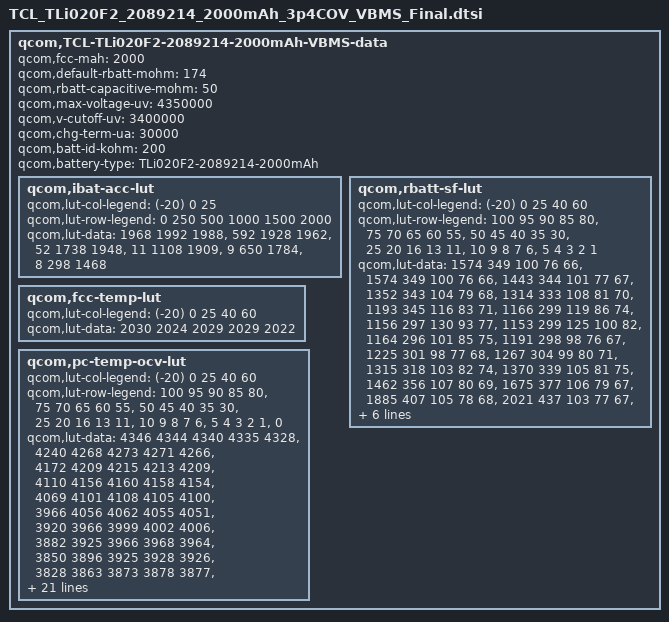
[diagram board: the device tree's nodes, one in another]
 qcom,TCL-TLi020F2-2089214-2000mAh-VBMS-data {
	qcom,fcc-mah = <2000>;
	qcom,default-rbatt-mohm = <174>;
	qcom,rbatt-capacitive-mohm = <50>;
	qcom,max-voltage-uv = <4350000>;
	qcom,v-cutoff-uv = <3400000>;
	qcom,chg-term-ua = <30000>;
	qcom,batt-id-kohm = <200>;
	qcom,battery-type = "TLi020F2-2089214-2000mAh";

	qcom,ibat-acc-lut {
		qcom,lut-col-legend = <(-20) 0 25>;
		qcom,lut-row-legend = <0 250 500 1000 1500 2000>;
		qcom,lut-data = <1968 1992 1988>,
				<592 1928 1962>,
				<52 1738 1948>,
				<11 1108 1909>,
				<9 650 1784>,
				<8 298 1468>;
	};

	qcom,rbatt-sf-lut {
		qcom,lut-col-legend = <(-20) 0 25 40 60>;
		qcom,lut-row-legend = <100 95 90 85 80>,
				<75 70 65 60 55>,
				<50 45 40 35 30>,
				<25 20 16 13 11>,
				<10 9 8 7 6>,
				<5 4 3 2 1>;
		qcom,lut-data = <1574 349 100 76 66>,
				<1574 349 100 76 66>,
				<1443 344 101 77 67>,
				<1352 343 104 79 68>,
				<1314 333 108 81 70>,
				<1193 345 116 83 71>,
				<1166 299 119 86 74>,
				<1156 297 130 93 77>,
				<1153 299 125 100 82>,
				<1164 296 101 85 75>,
				<1191 298 98 76 67>,
				<1225 301 98 77 68>,
				<1267 304 99 80 71>,
				<1315 318 103 82 74>,
				<1370 339 105 81 75>,
				<1462 356 107 80 69>,
				<1675 377 106 79 67>,
				<1885 407 105 78 68>,
				<2021 437 103 77 67>,
				<1834 430 103 78 68>,
				<1977 443 105 79 70>,
				<2151 459 109 82 71>,
				<2349 478 113 84 74>,
				<2593 497 118 87 76>,
				<2906 517 123 89 78>,
				<3354 537 122 86 71>,
				<4026 560 121 85 73>,
				<5346 602 129 92 78>,
				<10692 668 156 113 98>,
				<21384 1336 313 226 124>;
	};

	qcom,fcc-temp-lut {
		qcom,lut-col-legend = <(-20) 0 25 40 60>;
		qcom,lut-data = <2030 2024 2029 2029 2022>;
	};

	qcom,pc-temp-ocv-lut {
		qcom,lut-col-legend = <(-20) 0 25 40 60>;
		qcom,lut-row-legend = <100 95 90 85 80>,
				<75 70 65 60 55>,
				<50 45 40 35 30>,
				<25 20 16 13 11>,
				<10 9 8 7 6>,
				<5 4 3 2 1>,
				<0>;
		qcom,lut-data = <4346 4344 4340 4335 4328>,
				<4240 4268 4273 4271 4266>,
				<4172 4209 4215 4213 4209>,
				<4110 4156 4160 4158 4154>,
				<4069 4101 4108 4105 4100>,
				<3966 4056 4062 4055 4051>,
				<3920 3966 3999 4002 4006>,
				<3882 3925 3966 3968 3964>,
				<3850 3896 3925 3928 3926>,
				<3828 3863 3873 3878 3877>,
				<3812 3835 3842 3842 3841>,
				<3796 3811 3818 3818 3817>,
				<3782 3792 3799 3800 3798>,
				<3767 3779 3784 3783 3782>,
				<3752 3768 3772 3769 3766>,
				<3734 3753 3762 3754 3742>,
				<3714 3734 3742 3734 3720>,
				<3693 3719 3714 3706 3693>,
				<3673 3710 3694 3686 3672>,
				<3656 3703 3690 3682 3670>,
				<3645 3700 3689 3681 3669>,
				<3633 3696 3688 3680 3668>,
				<3618 3692 3687 3679 3667>,
				<3600 3686 3684 3677 3665>,
				<3576 3674 3676 3668 3656>,
				<3545 3652 3652 3642 3624>,
				<3502 3613 3602 3590 3572>,
				<3442 3555 3531 3520 3504>,
				<3342 3468 3432 3423 3417>,
				<3220 3328 3266 3254 3262>,
				<3000 3000 3000 3000 3000>;
	};
};
